# C7X256V_DEBUG_C7X256V_DEBUG_DBG_AGR0_MEM_CFG_000734040100h register map
Vendor: Texas Instruments
Peripheral module from a debugger description file (folder AM275x).
Registers are 32-bit, read-write, reset 0x0 unless marked. A register's access mark holds for its fields unless they carry their own. Offsets are as the file gives them; lines under a group give offsets from that group; [hi:lo] are bit positions; {n}, {i} and the like mark numbered series; 'fields as' and 'values as' point back to an identical list; <NAME> marks a mode.

## C7X256V_DEBUG_DBG_AGR0_MEM_CFG
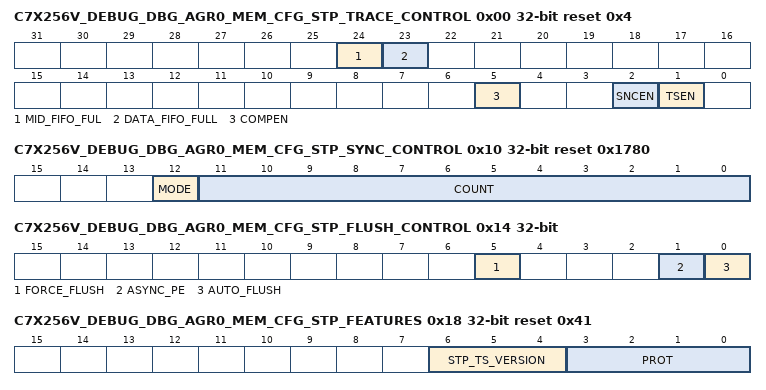
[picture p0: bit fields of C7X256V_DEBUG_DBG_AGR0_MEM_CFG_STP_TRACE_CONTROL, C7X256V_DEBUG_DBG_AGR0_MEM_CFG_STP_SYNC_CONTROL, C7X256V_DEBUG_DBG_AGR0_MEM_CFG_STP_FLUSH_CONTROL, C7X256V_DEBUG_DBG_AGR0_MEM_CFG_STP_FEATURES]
0x00 C7X256V_DEBUG_DBG_AGR0_MEM_CFG_STP_TRACE_CONTROL access per field reset 0x4 — This register contains the control and status settings for STP Trace control register. MID_Fifofull indicates status of internal Initiator/Channel Fifo as full. Data_Fifofull indicates the status of internal Data Fifo as full. It is possible that if MID_Fifofull is full and when new initiator_id is seen on STPMI i/f, the data will not be accepted as MID is full. It will wait for MID to be read out corresponding to Data.
  [24] MID_FIFO_FUL ro — '1' indicates STPMI2ATB internal MID packet fifo is full
  [23] DATA_FIFO_FULL ro — '1' indicates STPMI2ATB internal Data packet fifo is full
  [5] COMPEN rw — Compression Enable: '1' Enables compression of data. '0' disables data compress.
  [2] SNCEN ro — ASYNC Enable: 1 indicates STPASYNC is supported. 0 indicates STPASYNC is not supported.
  [1] TSEN rw — Timestamp Enable: 1 enables Timestamp. 0 disables Timestamp (it includes only a nibble TS, when disabled and a time-stamp is indicated on STPMI interface). This bit is static and should not be changed dynamically. This should be changed before client is enabled. The first TS packet sent out after ASYNC export will have either 64/48 (based on TSMAXWIDTH) bit timestamp and followed by only 4 bit Timestamp for TS packets.
0x04 C7X256V_DEBUG_DBG_AGR0_MEM_CFG_STP_TRACE_ID — This register contains the trace id register settings. This value is sampled from input and is exported on ATB interface as ATID field. This is usually programmed only when top-level configuration errors results in collision between ID's.
  [6:0] TRACEID — Traceid [6:0] value that is forwarded on the ATID interface for all transactions from the Trace Aggreator. The reset value is determined by a tieoff to STPMI2ATB and should be tied to 0000000b internal to the Trace Aggregator. SW must set this to a unique value in the the ATB ID address space to prevent collisions with other ATB sources.
0x10 C7X256V_DEBUG_DBG_AGR0_MEM_CFG_STP_SYNC_CONTROL reset 0x1780 — This register contains the periodic interval after which an ASYNC packet is exported over ATB interface. This counter register controls the interval between synchronization packets. The number of bytes between which a sync packet is sent based on this counter value. Writing a value of 0x0 disables the synchronization counter, however if the client has any other synchronization scheme, that will continue to operate.When this register is written, STPMI2ATB will immediately perform synchronization and reset the counter value to the newly programmed value ensuring subsequent synchronization occurs in the period programmed.This async requests will result in a Initiator switch. A async request will result in async packet followed by VERSION packet which is followed by a new M8/C8 packet before any Dx packet is sent.
  [12] MODE — Sync Count Mode: 1 indicates SYNC is 2N bytes N being derived from 11:7, value being between 12 and 27 inclusive 0 indicates N, where N is number of bytes between the ASYNC packets Counter = 2^ N, where [N = 2^m, m=11:7, 12 and 27 inclusive] (mode =1) Counter = N, where [N = 11:0] (mode =0)
  [11:0] COUNT — Period Count: Counts the number of bytes between Synchronization packets.
0x14 C7X256V_DEBUG_DBG_AGR0_MEM_CFG_STP_FLUSH_CONTROL — This register contains the bits to indicate flush in STPMI2ATB. It also controls priority control for other conditions in STPMI2ATB.
  [5] FORCE_FLUSH — Forces a flush operation: 1 indicates force a flush, automatically clears after the operation is complete. Refer to 2.10. A '0' is not a valid value to be written at any point of time. It will be ignored. This flush will happen only after any current flush on ATB boundary is completed.
  [1] ASYNC_PE — ASYNC Sequence Priority Enable: 0 indicates ASYNC packet priority is lower than normal trace. 1 indicates priority escalates on second synchronization request
  [0] AUTO_FLUSH — Enable ATB Auto-flush: 0 indicates auto flush disabled. 1 indicates auto flush enabled. On every complete data (ATDATA:WIDTH) in the fifo written, data is exported out when ATREADY is asserted. This needs to be written only once before client IP enabled.
0x18 C7X256V_DEBUG_DBG_AGR0_MEM_CFG_STP_FEATURES ro reset 0x41 — This register contains the bits to indicate the features implemented in STPMI2ATB. It shows the VERSION packet implemented based on STP2.0 type of encoding timestamp packet. It also indicates what protocol is followed in the IP.
  [6:4] STP_TS_VERSION — Timestamp Version 3 = STP2.0 with Natural binary STP2.0 timestamps. 4 = STP2.0 with Gray STP2.0 timestamps.
  [3:0] PROT — Protocol Version: 0001 indicates STP2.0 protocol
